# EFR32MG26B611F2048IM48 register map
Vendor: Silicon Labs; Series: EFR32; File version: B
Registers are 32-bit, read-write, reset 0x0 unless marked. A register's access mark holds for its fields unless they carry their own. Offsets are from the block's base; [hi:lo] are bit positions; {n}, {i} and the like mark numbered series; 'fields as' and 'values as' point back to an identical list.

## AMUXCP0_NS — AMUXCP0_NS Registers
Base 0x59020000
Same registers: AMUXCP0_S 0x49020000
0x00 IPVERSION ro reset 0x2
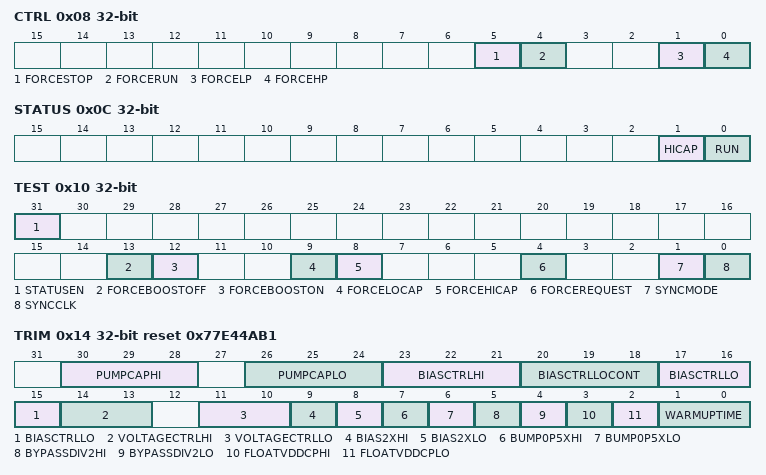
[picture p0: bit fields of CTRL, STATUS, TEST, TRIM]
0x08 CTRL — Control
  [5] FORCESTOP
  [4] FORCERUN
  [1] FORCELP — Force Low Power
  [0] FORCEHP — Force High Power
0x0C STATUS ro
  [1] HICAP — high cap
  [0] RUN — running
0x10 TEST
  [31] STATUSEN — Enable write to status bits
  [13] FORCEBOOSTOFF
  [12] FORCEBOOSTON
  [9] FORCELOCAP — Force low capacitance driver
  [8] FORCEHICAP — Force high capacitance driver
  [4] FORCEREQUEST
  [1] SYNCMODE
  [0] SYNCCLK — Sync Clock
0x14 TRIM reset 0x77E44AB1
  [30:28] PUMPCAPHI — Pump Cap High Power
  [26:24] PUMPCAPLO — Pump Cap Low Power
  [23:21] BIASCTRLHI — Bias Control High Power
  [20:18] BIASCTRLLOCONT — Bias Control Low Power Continuous
  [17:15] BIASCTRLLO — Bias Control Low Power
  [14:13] VOLTAGECTRLHI — Charge Pump Voltage Control High Power
  [11:10] VOLTAGECTRLLO — Charge Pump Voltage Control Low Power
  [9] BIAS2XHI — Bias 2x High Power
  [8] BIAS2XLO — Bias 2x Low Power
  [7] BUMP0P5XHI — Bump 0.5X High Power
  [6] BUMP0P5XLO — Bump 0.5X Low Power
  [5] BYPASSDIV2HI — Bypass Div2 High Power
  [4] BYPASSDIV2LO — Bypass Div2 Low Power
  [3] FLOATVDDCPHI — Float VDDCP High Power
  [2] FLOATVDDCPLO — Float VDDCP Low Power
  [1:0] WARMUPTIME
    0=WUCYCLES72 (Warm up cycle = 72; 3.6us @20 MHz); 1=WUCYCLES96 (Warm up cycle = 96; 4.8us @ 20 MHz); 2=WUCYCLES128 (Warm up cycle = 128; 6.4us @ 20 MHz); 3=WUCYCLES160 (Warm up cycle = 160; 8.0us @ 20 MHz)

## BURAM_NS — BURAM_NS Registers
Base 0x50084000
Same registers: BURAM_S 0x40084000
{0x0+4i} RET{i}_REG (i=0..31)
  [31:0] RETREG — Latch based Retention register

## BURTC_NS — BURTC_NS Registers
Base 0x5000C000
Same registers: BURTC_S 0x4000C000
0x00 IPVERSION ro reset 0x1
  [31:0] IPVERSION — IP Version ID
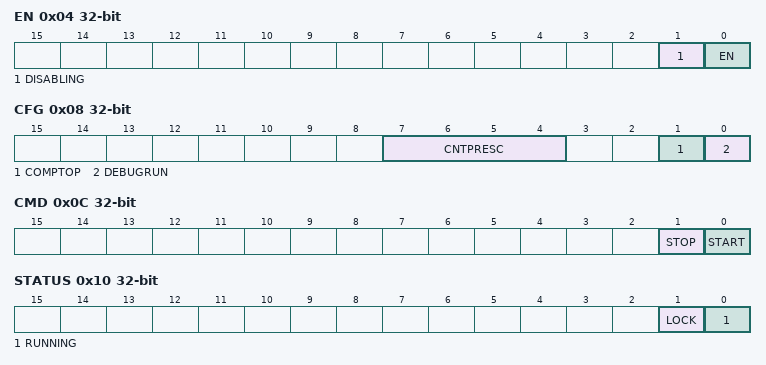
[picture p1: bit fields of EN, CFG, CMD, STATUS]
0x04 EN
  [1] DISABLING ro — Disablement busy status
  [0] EN — BURTC Enable
0x08 CFG
  [7:4] CNTPRESC — Counter prescaler value.
    0=DIV1 (CLK_CNT = (BURTC LF CLK)/1); 1=DIV2 (CLK_CNT = (BURTC LF CLK)/2); 2=DIV4 (CLK_CNT = (BURTC LF CLK)/4); 3=DIV8 (CLK_CNT = (BURTC LF CLK)/8); 4=DIV16 (CLK_CNT = (BURTC LF CLK)/16); 5=DIV32 (CLK_CNT = (BURTC LF CLK)/32); 6=DIV64 (CLK_CNT = (BURTC LF CLK)/64); 7=DIV128 (CLK_CNT = (BURTC LF CLK)/128); 8=DIV256 (CLK_CNT = (BURTC LF CLK)/256); 9=DIV512 (CLK_CNT = (BURTC LF CLK)/512); 10=DIV1024 (CLK_CNT = (BURTC LF CLK)/1024); 11=DIV2048 (CLK_CNT = (BURTC LF CLK)/2048); 12=DIV4096 (CLK_CNT = (BURTC LF CLK)/4096); 13=DIV8192 (CLK_CNT = (BURTC LF CLK)/8192); 14=DIV16384 (CLK_CNT = (BURTC LF CLK)/16384); 15=DIV32768 (CLK_CNT = (BURTC LF CLK)/32768)
  [1] COMPTOP — Compare Channel is Top Value
    0=DISABLE (The top value of the BURTC is 4294967295 (0xFFFFFFFF)); 1=ENABLE (The top value of the BURTC is given by COMP)
  [0] DEBUGRUN — Debug Mode Run Enable
    0=BURTC is frozen in debug mode; 1=BURTC is running in debug mode
0x0C CMD wo
  [1] STOP — Stop BURTC counter
  [0] START — Start BURTC counter
0x10 STATUS ro
  [1] LOCK — Configuration Lock Status
    0=UNLOCKED (All BURTC lockable registers are unlocked.); 1=LOCKED (All BURTC lockable registers are locked.)
  [0] RUNNING — BURTC running status
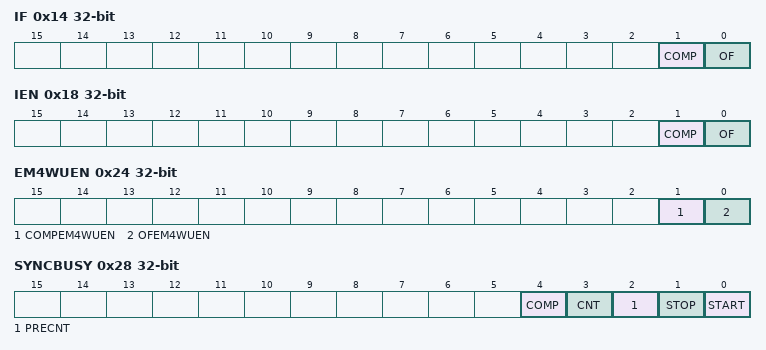
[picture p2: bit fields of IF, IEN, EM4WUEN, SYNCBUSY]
0x14 IF
  [1] COMP — Compare Match Interrupt Flag
  [0] OF — Overflow Interrupt Flag
0x18 IEN
  fields as IF
0x1C PRECNT
  [14:0] PRECNT — Pre-Counter Value
0x20 CNT
  [31:0] CNT — Counter Value
0x24 EM4WUEN
  [1] COMPEM4WUEN — Compare Match EM4 Wakeup Enable
  [0] OFEM4WUEN — Overflow EM4 Wakeup Enable
0x28 SYNCBUSY ro
  [4] COMP — Sync busy for COMP
  [3] CNT — Sync busy for CNT
  [2] PRECNT — Sync busy for PRECNT
  [1] STOP — Sync busy for STOP
  [0] START — Sync busy for START
0x2C LOCK wo reset 0xAEE8
  [15:0] LOCKKEY — Configuration Lock Key
    0xAEE8=UNLOCK (Write to unlock all BURTC lockable registers)
0x30 COMP
  [31:0] COMP — Compare Value
